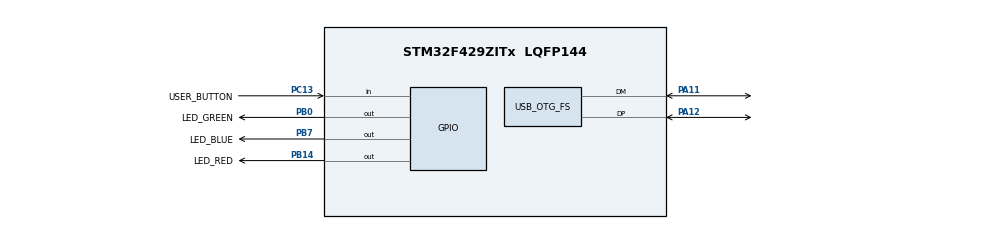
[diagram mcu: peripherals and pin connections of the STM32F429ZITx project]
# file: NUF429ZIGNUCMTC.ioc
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Mcu.Family=STM32F4
Mcu.Name=STM32F429ZITx
Mcu.Package=LQFP144
NVIC.OTG_FS_IRQn=true\:0\:0\:false\:false\:true\:false\:true\:true
NVIC.PriorityGroup=NVIC_PRIORITYGROUP_4
PA11.Mode=Device_Only
PA11.Signal=USB_OTG_FS_DM
PA12.Mode=Device_Only
PA12.Signal=USB_OTG_FS_DP
PA13.Mode=Trace_Asynchronous_SW
PA13.Signal=SYS_JTMS-SWDIO
PA14.Mode=Trace_Asynchronous_SW
PA14.Signal=SYS_JTCK-SWCLK
PB0.GPIO_Label=LED_GREEN
PB0.Signal=GPIO_Output
PB14.GPIO_Label=LED_RED
PB14.Signal=GPIO_Output
PB3.Mode=Trace_Asynchronous_SW
PB3.Signal=SYS_JTDO-SWO
PB7.GPIO_Label=LED_BLUE
PB7.Signal=GPIO_Output
PC13.GPIO_Label=USER_BUTTON
PC13.Signal=GPIO_Input
PH0/OSC_IN.Mode=HSE-External-Oscillator
PH0/OSC_IN.Signal=RCC_OSC_IN
PH1/OSC_OUT.Mode=HSE-External-Oscillator
PH1/OSC_OUT.Signal=RCC_OSC_OUT
ProjectManager.HeapSize=0x200
ProjectManager.StackSize=0x400
ProjectManager.TargetToolchain=STM32CubeIDE
RCC.48MHZClocksFreq_Value=48000000
RCC.AHBFreq_Value=144000000
RCC.APB1CLKDivider=RCC_HCLK_DIV4
RCC.APB1Freq_Value=36000000
RCC.APB1TimFreq_Value=72000000
RCC.APB2CLKDivider=RCC_HCLK_DIV2
RCC.APB2Freq_Value=72000000
RCC.APB2TimFreq_Value=144000000
RCC.CortexFreq_Value=144000000
RCC.HCLKFreq_Value=144000000
RCC.HSE_VALUE=8000000
RCC.HSI_VALUE=16000000
RCC.LSE_VALUE=32768
RCC.PLLM=4
RCC.PLLN=144
RCC.PLLQ=6
RCC.SYSCLKFreq_VALUE=144000000
RCC.SYSCLKSource=RCC_SYSCLKSOURCE_PLLCLK
RCC.VCOOutputFreq_Value=288000000
USB_DEVICE.CLASS_NAME_FS=AUDIO
USB_DEVICE.USBD_AUDIO_FREQ-AUDIO_FS=48000
USB_DEVICE.VirtualMode-AUDIO_FS=Audio
USB_DEVICE.VirtualModeFS=Audio_FS
USB_OTG_FS.VirtualMode=Device_Only
VP_USB_DEVICE_VS_USB_DEVICE_AUDIO_FS.Mode=AUDIO_FS
board=custom

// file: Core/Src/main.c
/* USER CODE BEGIN Header */
/**
  ******************************************************************************
  * @file           : main.c
  * @brief          : Main program body
  ******************************************************************************
  * @attention
  *
  * Copyright (c) 2022 STMicroelectronics.
  * All rights reserved.
  *
  * This software is licensed under terms that can be found in the LICENSE file
  * in the root directory of this software component.
  * If no LICENSE file comes with this software, it is provided AS-IS.
  *
  ******************************************************************************
  */
/* USER CODE END Header */
#include "main.h"
#include "usb_device.h"
#include "gpio.h"

/* USER CODE BEGIN Includes */
#include "myAppMain.h"
#include <stdio.h>
/* USER CODE END Includes */

void SystemClock_Config(void);

int main(void)
{

  /* MCU Configuration--------------------------------------------------------*/

  /* Reset of all peripherals, Initializes the Flash interface and the Systick. */
  HAL_Init();

  /* Configure the system clock */
  SystemClock_Config();

  /* Initialize all configured peripherals */
  MX_GPIO_Init();
  MX_USB_DEVICE_Init();

  /* Infinite loop */
  /* USER CODE BEGIN WHILE */
  projectMain();
  while (1)
  {
    /* USER CODE END WHILE */

  }
}

void SystemClock_Config(void)
{
  LL_FLASH_SetLatency(LL_FLASH_LATENCY_4);
  while(LL_FLASH_GetLatency()!= LL_FLASH_LATENCY_4)
  {
  }
  LL_PWR_SetRegulVoltageScaling(LL_PWR_REGU_VOLTAGE_SCALE1);
  LL_PWR_DisableOverDriveMode();
  LL_RCC_HSE_Enable();

   /* Wait till HSE is ready */
  while(LL_RCC_HSE_IsReady() != 1)
  {

  }
  LL_RCC_PLL_ConfigDomain_SYS(LL_RCC_PLLSOURCE_HSE, LL_RCC_PLLM_DIV_4, 144, LL_RCC_PLLP_DIV_2);
  LL_RCC_PLL_ConfigDomain_48M(LL_RCC_PLLSOURCE_HSE, LL_RCC_PLLM_DIV_4, 144, LL_RCC_PLLQ_DIV_6);
  LL_RCC_PLL_Enable();

   /* Wait till PLL is ready */
  while(LL_RCC_PLL_IsReady() != 1)
  {

  }
  while (LL_PWR_IsActiveFlag_VOS() == 0)
  {
  }
  LL_RCC_SetAHBPrescaler(LL_RCC_SYSCLK_DIV_1);
  LL_RCC_SetAPB1Prescaler(LL_RCC_APB1_DIV_4);
  LL_RCC_SetAPB2Prescaler(LL_RCC_APB2_DIV_2);
  LL_RCC_SetSysClkSource(LL_RCC_SYS_CLKSOURCE_PLL);

   /* Wait till System clock is ready */
  while(LL_RCC_GetSysClkSource() != LL_RCC_SYS_CLKSOURCE_STATUS_PLL)
  {

  }
  LL_SetSystemCoreClock(144000000);

   /* Update the time base */
  if (HAL_InitTick (TICK_INT_PRIORITY) != HAL_OK)
  {
    Error_Handler();
  }
  LL_RCC_SetTIMPrescaler(LL_RCC_TIM_PRESCALER_TWICE);
}

void Error_Handler(void)
{
  __disable_irq();
  while (1)
  {
  }
}
